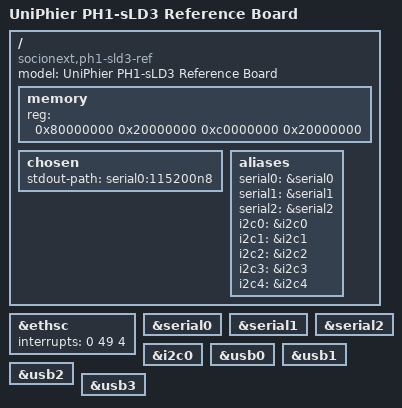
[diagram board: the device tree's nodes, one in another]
/*
 * Device Tree Source for UniPhier PH1-sLD3 Reference Board
 *
 * Copyright (C) 2015 Masahiro Yamada <yamada.masahiro@socionext.com>
 *
 * This file is dual-licensed: you can use it either under the terms
 * of the GPL or the X11 license, at your option. Note that this dual
 * licensing only applies to this file, and not this project as a
 * whole.
 *
 *  a) This file is free software; you can redistribute it and/or
 *     modify it under the terms of the GNU General Public License as
 *     published by the Free Software Foundation; either version 2 of the
 *     License, or (at your option) any later version.
 *
 *     This file is distributed in the hope that it will be useful,
 *     but WITHOUT ANY WARRANTY; without even the implied warranty of
 *     MERCHANTABILITY or FITNESS FOR A PARTICULAR PURPOSE.  See the
 *     GNU General Public License for more details.
 *
 * Or, alternatively,
 *
 *  b) Permission is hereby granted, free of charge, to any person
 *     obtaining a copy of this software and associated documentation
 *     files (the "Software"), to deal in the Software without
 *     restriction, including without limitation the rights to use,
 *     copy, modify, merge, publish, distribute, sublicense, and/or
 *     sell copies of the Software, and to permit persons to whom the
 *     Software is furnished to do so, subject to the following
 *     conditions:
 *
 *     The above copyright notice and this permission notice shall be
 *     included in all copies or substantial portions of the Software.
 *
 *     THE SOFTWARE IS PROVIDED "AS IS", WITHOUT WARRANTY OF ANY KIND,
 *     EXPRESS OR IMPLIED, INCLUDING BUT NOT LIMITED TO THE WARRANTIES
 *     OF MERCHANTABILITY, FITNESS FOR A PARTICULAR PURPOSE AND
 *     NONINFRINGEMENT. IN NO EVENT SHALL THE AUTHORS OR COPYRIGHT
 *     HOLDERS BE LIABLE FOR ANY CLAIM, DAMAGES OR OTHER LIABILITY,
 *     WHETHER IN AN ACTION OF CONTRACT, TORT OR OTHERWISE, ARISING
 *     FROM, OUT OF OR IN CONNECTION WITH THE SOFTWARE OR THE USE OR
 *     OTHER DEALINGS IN THE SOFTWARE.
 */

/dts-v1/;
/include/ "uniphier-ph1-sld3.dtsi"
/include/ "uniphier-ref-daughter.dtsi"
/include/ "uniphier-support-card.dtsi"

/ {
	model = "UniPhier PH1-sLD3 Reference Board";
	compatible = "socionext,ph1-sld3-ref", "socionext,ph1-sld3";

	memory {
		device_type = "memory";
		reg = <0x80000000 0x20000000
		       0xc0000000 0x20000000>;
	};

	chosen {
		stdout-path = "serial0:115200n8";
	};

	aliases {
		serial0 = &serial0;
		serial1 = &serial1;
		serial2 = &serial2;
		i2c0 = &i2c0;
		i2c1 = &i2c1;
		i2c2 = &i2c2;
		i2c3 = &i2c3;
		i2c4 = &i2c4;
	};
};

&ethsc {
	interrupts = <0 49 4>;
};

&serial0 {
	status = "okay";
};

&serial1 {
	status = "okay";
};

&serial2 {
	status = "okay";
};

&i2c0 {
	status = "okay";
};

&usb0 {
	status = "okay";
};

&usb1 {
	status = "okay";
};

&usb2 {
	status = "okay";
};

&usb3 {
	status = "okay";
};
